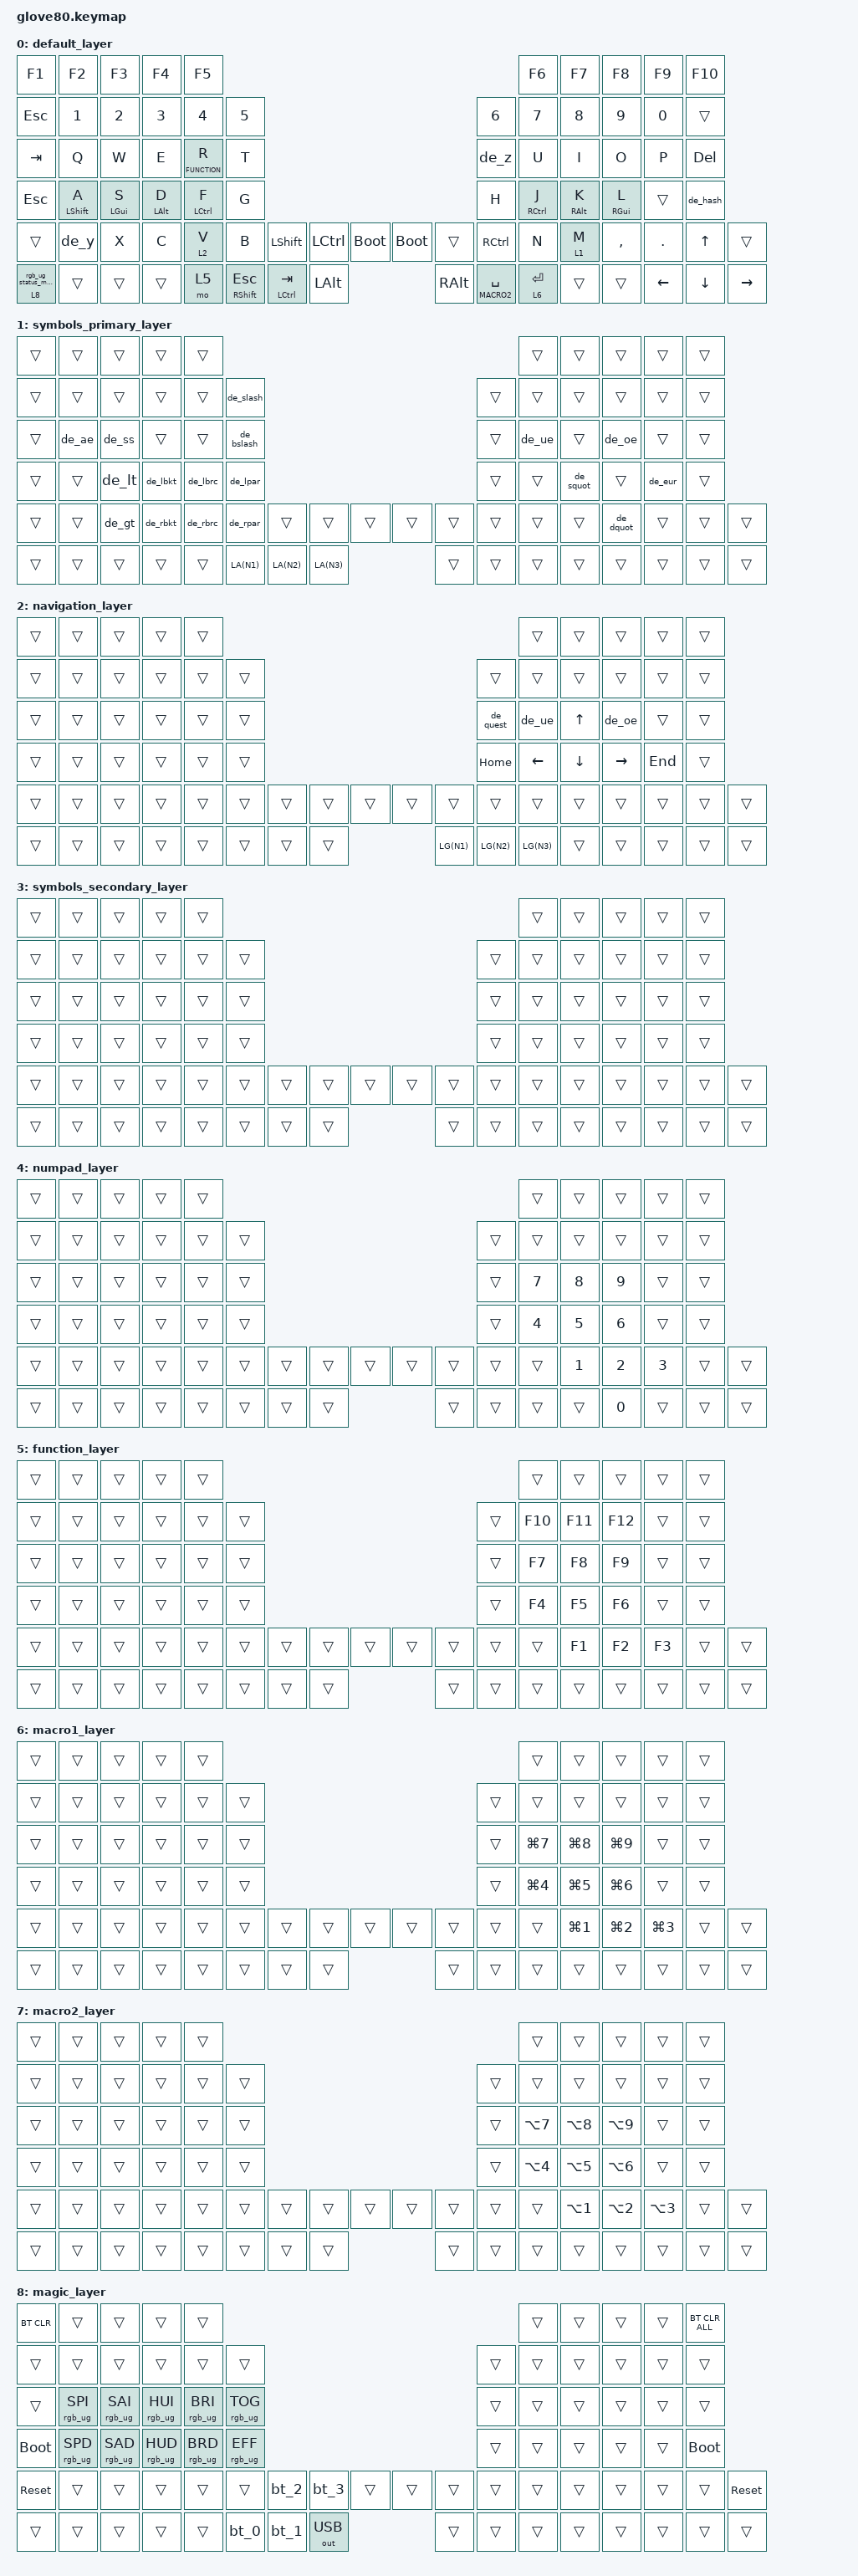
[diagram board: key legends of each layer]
#include <behaviors.dtsi>
#include <dt-bindings/zmk/bt.h>
#include <dt-bindings/zmk/keys.h>
#include <dt-bindings/zmk/outputs.h>
#include <dt-bindings/zmk/rgb.h>

// German umlauts and special characters >
#define DE_ESCAPE_CHARACTER (LC(ZMK_HID_USAGE(HID_USAGE_KEY, HID_USAGE_KEY_KEYBOARD_LEFT_BRACKET_AND_LEFT_BRACE)))
#define DE_FILE_SEPARATOR (LC(ZMK_HID_USAGE(HID_USAGE_KEY, HID_USAGE_KEY_KEYBOARD_BACKSLASH_AND_PIPE)))
#define DE_GROUP_SEPARATOR (LC(ZMK_HID_USAGE(HID_USAGE_KEY, HID_USAGE_KEY_KEYBOARD_RIGHT_BRACKET_AND_RIGHT_BRACE)))
#define DE_SPACE (ZMK_HID_USAGE(HID_USAGE_KEY, HID_USAGE_KEY_KEYBOARD_SPACEBAR))
#define DE_EXCLAMATION (LS(ZMK_HID_USAGE(HID_USAGE_KEY, HID_USAGE_KEY_KEYBOARD_1_AND_EXCLAMATION)))
#define DE_DOUBLE_QUOTES (LS(ZMK_HID_USAGE(HID_USAGE_KEY, HID_USAGE_KEY_KEYBOARD_2_AND_AT)))
#define DE_HASH (ZMK_HID_USAGE(HID_USAGE_KEY, HID_USAGE_KEY_KEYBOARD_BACKSLASH_AND_PIPE))
#define DE_DOLLAR (LS(ZMK_HID_USAGE(HID_USAGE_KEY, HID_USAGE_KEY_KEYBOARD_4_AND_DOLLAR)))
#define DE_PERCENT (LS(ZMK_HID_USAGE(HID_USAGE_KEY, HID_USAGE_KEY_KEYBOARD_5_AND_PERCENT)))
#define DE_AMPERSAND (LS(ZMK_HID_USAGE(HID_USAGE_KEY, HID_USAGE_KEY_KEYBOARD_6_AND_CARET)))
#define DE_SINGLE_QUOTE (LS(ZMK_HID_USAGE(HID_USAGE_KEY, HID_USAGE_KEY_KEYBOARD_BACKSLASH_AND_PIPE)))
#define DE_LEFT_PARENTHESIS (LS(ZMK_HID_USAGE(HID_USAGE_KEY, HID_USAGE_KEY_KEYBOARD_8_AND_ASTERISK)))
#define DE_RIGHT_PARENTHESIS (LS(ZMK_HID_USAGE(HID_USAGE_KEY, HID_USAGE_KEY_KEYBOARD_9_AND_LEFT_PARENTHESIS)))
#define DE_ASTERISK (LS(ZMK_HID_USAGE(HID_USAGE_KEY, HID_USAGE_KEY_KEYBOARD_RIGHT_BRACKET_AND_RIGHT_BRACE)))
#define DE_PLUS (ZMK_HID_USAGE(HID_USAGE_KEY, HID_USAGE_KEY_KEYBOARD_RIGHT_BRACKET_AND_RIGHT_BRACE))
#define DE_COMMA (ZMK_HID_USAGE(HID_USAGE_KEY, HID_USAGE_KEY_KEYBOARD_COMMA_AND_LESS_THAN))
#define DE_MINUS (ZMK_HID_USAGE(HID_USAGE_KEY, HID_USAGE_KEY_KEYBOARD_SLASH_AND_QUESTION_MARK))
#define DE_PERIOD (ZMK_HID_USAGE(HID_USAGE_KEY, HID_USAGE_KEY_KEYBOARD_PERIOD_AND_GREATER_THAN))
#define DE_SLASH (LS(ZMK_HID_USAGE(HID_USAGE_KEY, HID_USAGE_KEY_KEYBOARD_7_AND_AMPERSAND)))
#define DE_N0 (ZMK_HID_USAGE(HID_USAGE_KEY, HID_USAGE_KEY_KEYBOARD_0_AND_RIGHT_PARENTHESIS))
#define DE_N1 (ZMK_HID_USAGE(HID_USAGE_KEY, HID_USAGE_KEY_KEYBOARD_1_AND_EXCLAMATION))
#define DE_N2 (ZMK_HID_USAGE(HID_USAGE_KEY, HID_USAGE_KEY_KEYBOARD_2_AND_AT))
#define DE_N3 (ZMK_HID_USAGE(HID_USAGE_KEY, HID_USAGE_KEY_KEYBOARD_3_AND_HASH))
#define DE_N4 (ZMK_HID_USAGE(HID_USAGE_KEY, HID_USAGE_KEY_KEYBOARD_4_AND_DOLLAR))
#define DE_N5 (ZMK_HID_USAGE(HID_USAGE_KEY, HID_USAGE_KEY_KEYBOARD_5_AND_PERCENT))
#define DE_N6 (ZMK_HID_USAGE(HID_USAGE_KEY, HID_USAGE_KEY_KEYBOARD_6_AND_CARET))
#define DE_N7 (ZMK_HID_USAGE(HID_USAGE_KEY, HID_USAGE_KEY_KEYBOARD_7_AND_AMPERSAND))
#define DE_N8 (ZMK_HID_USAGE(HID_USAGE_KEY, HID_USAGE_KEY_KEYBOARD_8_AND_ASTERISK))
#define DE_N9 (ZMK_HID_USAGE(HID_USAGE_KEY, HID_USAGE_KEY_KEYBOARD_9_AND_LEFT_PARENTHESIS))
#define DE_COLON (LS(ZMK_HID_USAGE(HID_USAGE_KEY, HID_USAGE_KEY_KEYBOARD_PERIOD_AND_GREATER_THAN)))
#define DE_SEMICOLON (LS(ZMK_HID_USAGE(HID_USAGE_KEY, HID_USAGE_KEY_KEYBOARD_COMMA_AND_LESS_THAN)))
#define DE_LESS_THAN (ZMK_HID_USAGE(HID_USAGE_KEY, HID_USAGE_KEY_KEYBOARD_NON_US_BACKSLASH_AND_PIPE))
#define DE_EQUAL (LS(ZMK_HID_USAGE(HID_USAGE_KEY, HID_USAGE_KEY_KEYBOARD_0_AND_RIGHT_PARENTHESIS)))
#define DE_GREATER_THAN (LS(ZMK_HID_USAGE(HID_USAGE_KEY, HID_USAGE_KEY_KEYBOARD_NON_US_BACKSLASH_AND_PIPE)))
#define DE_QUESTION (LS(ZMK_HID_USAGE(HID_USAGE_KEY, HID_USAGE_KEY_KEYBOARD_MINUS_AND_UNDERSCORE)))
#define DE_AT_SIGN (RA(ZMK_HID_USAGE(HID_USAGE_KEY, HID_USAGE_KEY_KEYBOARD_Q)))
#define DE_LEFT_BRACKET (RA(ZMK_HID_USAGE(HID_USAGE_KEY, HID_USAGE_KEY_KEYBOARD_8_AND_ASTERISK)))
#define DE_BACKSLASH (RA(ZMK_HID_USAGE(HID_USAGE_KEY, HID_USAGE_KEY_KEYBOARD_MINUS_AND_UNDERSCORE)))
#define DE_RIGHT_BRACKET (RA(ZMK_HID_USAGE(HID_USAGE_KEY, HID_USAGE_KEY_KEYBOARD_9_AND_LEFT_PARENTHESIS)))
#define DE_CARET (ZMK_HID_USAGE(HID_USAGE_KEY, HID_USAGE_KEY_KEYBOARD_GRAVE_ACCENT_AND_TILDE))
#define DE_UNDERSCORE (LS(ZMK_HID_USAGE(HID_USAGE_KEY, HID_USAGE_KEY_KEYBOARD_SLASH_AND_QUESTION_MARK)))
#define DE_GRAVE (LS(ZMK_HID_USAGE(HID_USAGE_KEY, HID_USAGE_KEY_KEYBOARD_EQUAL_AND_PLUS)))
#define DE_Y (ZMK_HID_USAGE(HID_USAGE_KEY, HID_USAGE_KEY_KEYBOARD_Z))
#define DE_Z (ZMK_HID_USAGE(HID_USAGE_KEY, HID_USAGE_KEY_KEYBOARD_Y))
#define DE_LEFT_BRACE (RA(ZMK_HID_USAGE(HID_USAGE_KEY, HID_USAGE_KEY_KEYBOARD_7_AND_AMPERSAND)))
#define DE_PIPE (RA(ZMK_HID_USAGE(HID_USAGE_KEY, HID_USAGE_KEY_KEYBOARD_NON_US_BACKSLASH_AND_PIPE)))
#define DE_RIGHT_BRACE (RA(ZMK_HID_USAGE(HID_USAGE_KEY, HID_USAGE_KEY_KEYBOARD_0_AND_RIGHT_PARENTHESIS)))
#define DE_TILDE (RA(ZMK_HID_USAGE(HID_USAGE_KEY, HID_USAGE_KEY_KEYBOARD_RIGHT_BRACKET_AND_RIGHT_BRACE)))
#define DE_SECTION (LS(ZMK_HID_USAGE(HID_USAGE_KEY, HID_USAGE_KEY_KEYBOARD_3_AND_HASH)))
#define DE_DEGREE (LS(ZMK_HID_USAGE(HID_USAGE_KEY, HID_USAGE_KEY_KEYBOARD_GRAVE_ACCENT_AND_TILDE)))
#define DE_SUPER2 (RA(ZMK_HID_USAGE(HID_USAGE_KEY, HID_USAGE_KEY_KEYBOARD_2_AND_AT)))
#define DE_SUPER3 (RA(ZMK_HID_USAGE(HID_USAGE_KEY, HID_USAGE_KEY_KEYBOARD_3_AND_HASH)))
#define DE_ACUTE (ZMK_HID_USAGE(HID_USAGE_KEY, HID_USAGE_KEY_KEYBOARD_EQUAL_AND_PLUS))
#define DE_SHARP_S (LS(RA(ZMK_HID_USAGE(HID_USAGE_KEY, HID_USAGE_KEY_KEYBOARD_MINUS_AND_UNDERSCORE))))
#define DE_A_UMLAUT (ZMK_HID_USAGE(HID_USAGE_KEY, HID_USAGE_KEY_KEYBOARD_APOSTROPHE_AND_QUOTE))
#define DE_O_UMLAUT (ZMK_HID_USAGE(HID_USAGE_KEY, HID_USAGE_KEY_KEYBOARD_SEMICOLON_AND_COLON))
#define DE_U_UMLAUT (ZMK_HID_USAGE(HID_USAGE_KEY, HID_USAGE_KEY_KEYBOARD_LEFT_BRACKET_AND_LEFT_BRACE))
#define DE_EURO (RA(ZMK_HID_USAGE(HID_USAGE_KEY, HID_USAGE_KEY_KEYBOARD_E)))
// < German umlauts and special characters

// layers
#define DEFAULT 0
#define SYMBOLS_PRIMARY 1
#define NAVIGATION 2
#define SYMBOLS_SECONDARY 3
#define NUMPAD 4
#define FUNCTION 5
#define MACRO1 6
#define MACRO2 7
#define MAGIC 8

/ {
    // Positionsnummern für alle Tasten (für Kombos und andere Referenzen)
    // |  0       |  1      |  2       |  3        |  4         |                                                                                  |  5     |  6       |  7        |   8       |  9   |
    // |  10      |  11     |  12      |  13       |  14        |  15   |                                                                  |  16   |   17   |   18     |  19       |   20      |   21 |
    // |  22      |  23     |  24      |  25       |  26        |  27   |                                                                  |  28   |   29   |   30 I   |  31       |   32      |   33 |
    // |  34      |  35     |  36      |  37       |  38        |  39   |                                                                  |  40   |   41 J |   42 K   |  43       |   44      |   45 |
    // |  46      |  47     |  48      |  49       |  50        |  51   |   52      |   53      |   54    |  |   55    |   56    |   57    |  58   |   59   |   60 ,   |  61       |   62      |   63 |
    // |  64      |  65     |  66      |  67       |  68        |       |   69      |   70      |   71    |  |   72    |   73    |   74    |       |   75   |   76     |  77       |   78      |   79 |

    combos {
        compatible = "zmk,combos";

        // backspace jk

        combo_bspc {
            timeout-ms = <50>;
            key-positions = <41 42>; // J and K keys
            bindings = <&kp BACKSPACE>;
            layers = <0>;
        };

        // arrow up - I and K keys

        combo_up {
            timeout-ms = <50>;
            key-positions = <30 42>; // I and K keys
            bindings = <&kp UP>;
            layers = <0>;
        };

        // arrow down - K and comma keys

        combo_down {
            timeout-ms = <50>;
            key-positions = <42 60>; // K and comma keys
            bindings = <&kp DOWN>;
            layers = <0>;
        };

        //
        // // left bracket - U and I keys
        // combo_lbrc {
        //     timeout-ms = <50>;
        //     key-positions = <29 30>; // U and I keys
        //     bindings = <&kp LBKT>;
        //     layers = <0>;
        // };
        //
        // // right bracket - I and O keys
        // combo_rbrc {
        //     timeout-ms = <50>;
        //     key-positions = <30 31>; // I and O keys
        //     bindings = <&kp RBKT>;
        //     layers = <0>;
        // };
        //
        // // right curly brace - comma and dot keys
        // combo_rcbr {
        //     timeout-ms = <50>;
        //     key-positions = <60 61>; // comma and dot keys
        //     bindings = <&kp RBRC>;
        //     layers = <0>;
        // };
        //
        // // left parenthesis - 7 and 8 keys
        // combo_lprn {
        //     timeout-ms = <50>;
        //     key-positions = <17 18>; // 7 and 8 keys
        //     bindings = <&kp LPAR>;
        //     layers = <0>;
        // };
        //
        // // right parenthesis - 8 and 9 keys
        // combo_rprn {
        //     timeout-ms = <50>;
        //     key-positions = <18 19>; // 8 and 9 keys
        //     bindings = <&kp RPAR>;
        //     layers = <0>;
        // };
        //
        // // left curly brace - M and comma keys
        // combo_lcbr {
        //     timeout-ms = <50>;
        //     key-positions = <59 60>; // M and comma keys
        //     bindings = <&kp LBRC>;
        //     layers = <0>;
        // };
        //
        // // enter - J and M keys
        // combo_enter {
        //     timeout-ms = <50>;
        //     key-positions = <41 59>; // J and M keys
        //     bindings = <&kp ENTER>;
        //     layers = <0>;
        // };
        //
        // // tab - P and minus keys
        // combo_tab {
        //     timeout-ms = <50>;
        //     key-positions = <32 62>; // P and minus keys
        //     bindings = <&kp TAB>;
        //     layers = <0>;
        // };
    };

    behaviors {
        // For the "layer" key, it'd nice to be able to use it as either a shift or a toggle.
        // Configure it as a tap dance, so the first tap (or hold) is a &mo and the second tap is a &to
        // layer_td: tap_dance_0 {
        //     compatible = "zmk,behavior-tap-dance";
        //     label = "LAYER_TAP_DANCE";
        //     #binding-cells = <0>;
        //     tapping-term-ms = <200>;
        //     bindings = <&mo LOWER>, <&to LOWER>;
        // };

        magic: magic_hold_tap {
            compatible = "zmk,behavior-hold-tap";
            #binding-cells = <2>;
            flavor = "tap-preferred";
            tapping-term-ms = <200>;
            bindings = <&mo>, <&rgb_ug_status_macro>;
        };

        hm: homerow_mods {
            compatible = "zmk,behavior-hold-tap";
            #binding-cells = <2>;
            tapping-term-ms = <250>;
            quick-tap-ms = <0>;
            flavor = "tap-preferred";
            bindings = <&kp>, <&kp>;
        };
        
        mx: mx {
            compatible = "zmk,behavior-hold-tap";
            #binding-cells = <2>;
            tapping-term-ms = <250>;
            flavor = "tap-preferred";
            bindings = <&mo>, <&kp>;
        };
    };

macros {
        rgb_ug_status_macro: rgb_ug_status_macro_0 {
            label = "RGB_UG_STATUS";
            compatible = "zmk,behavior-macro";
            #binding-cells = <0>;
            bindings = <&rgb_ug RGB_STATUS>;
        };
 
        // German umlauts and special characters

        de_ae: de_ae { compatible = "zmk,behavior-macro"; #binding-cells = <0>; bindings = <&kp DE_A_UMLAUT>; };  // ä
        de_ss: de_ss { compatible = "zmk,behavior-macro"; #binding-cells = <0>; bindings = <&kp DE_SHARP_S>; };  // ß
        de_oe: de_oe { compatible = "zmk,behavior-macro"; #binding-cells = <0>; bindings = <&kp DE_O_UMLAUT>; };  // ö
        de_ue: de_ue { compatible = "zmk,behavior-macro"; #binding-cells = <0>; bindings = <&kp DE_U_UMLAUT>; };  // ü
        de_eur: de_eur { compatible = "zmk,behavior-macro"; #binding-cells = <0>; bindings = <&kp DE_EURO>; };  // €
        de_sect: de_sect { compatible = "zmk,behavior-macro"; #binding-cells = <0>; bindings = <&kp DE_SECTION>; };  // §
        de_deg: de_deg { compatible = "zmk,behavior-macro"; #binding-cells = <0>; bindings = <&kp DE_DEGREE>; };  // °
        de_square: de_square { compatible = "zmk,behavior-macro"; #binding-cells = <0>; bindings = <&kp DE_SUPER2>; };  // ²
        de_cube: de_cube { compatible = "zmk,behavior-macro"; #binding-cells = <0>; bindings = <&kp DE_SUPER3>; };  // ³
        de_acute: de_acute { compatible = "zmk,behavior-macro"; #binding-cells = <0>; bindings = <&kp DE_ACUTE>; };  // ´
        de_y: de_y { compatible = "zmk,behavior-macro"; #binding-cells = <0>; bindings = <&kp DE_Y>; };  // y (on German layout)
        de_z: de_z { compatible = "zmk,behavior-macro"; #binding-cells = <0>; bindings = <&kp DE_Z>; };  // z (on German layout)
        de_excl: de_excl { compatible =   "zmk,behavior-macro"; #binding-cells = <0>; bindings = <&kp DE_EXCLAMATION>; };  // !
        de_dollar: de_dollar { compatible = "zmk,behavior-macro"; #binding-cells = <0>; bindings = <&kp DE_DOLLAR>; };  // $
        de_percent: de_percent { compatible = "zmk,behavior-macro"; #binding-cells = <0>; bindings = <&kp DE_PERCENT>; };  // %
        de_plus: de_plus { compatible = "zmk,behavior-macro"; #binding-cells = <0>; bindings = <&kp DE_PLUS>; };  // +
        de_comma: de_comma { compatible = "zmk,behavior-macro"; #binding-cells = <0>; bindings = <&kp DE_COMMA>; };  // ,
        de_minus: de_minus { compatible = "zmk,behavior-macro"; #binding-cells = <0>; bindings = <&kp DE_MINUS>; };  // -
        de_period: de_period { compatible = "zmk,behavior-macro"; #binding-cells = <0>; bindings = <&kp DE_PERIOD>; };  // .
        de_colon: de_colon { compatible = "zmk,behavior-macro"; #binding-cells = <0>; bindings = <&kp DE_COLON>; };  // :
        de_semi: de_semi { compatible = "zmk,behavior-macro"; #binding-cells = <0>; bindings = <&kp DE_SEMICOLON>; };  // ;
        de_caret: de_caret { compatible = "zmk,behavior-macro"; #binding-cells = <0>; bindings = <&kp DE_CARET>; };  // ^
        de_under: de_under { compatible = "zmk,behavior-macro"; #binding-cells = <0>; bindings = <&kp DE_UNDERSCORE>; };  // _
        de_grave: de_grave { compatible = "zmk,behavior-macro"; #binding-cells = <0>; bindings = <&kp DE_GRAVE>; };  // `

        de_lt: de_lt { compatible = "zmk,behavior-macro"; #binding-cells = <0>; bindings = <&kp DE_LESS_THAN>; };  // <
        de_gt: de_gt { compatible = "zmk,behavior-macro"; #binding-cells = <0>; bindings = <&kp DE_GREATER_THAN>; };  // >
        de_lbkt: de_lbkt { compatible = "zmk,behavior-macro"; #binding-cells = <0>; bindings = <&kp DE_LEFT_BRACKET>; };  // [
        de_rbkt: de_rbkt { compatible = "zmk,behavior-macro"; #binding-cells = <0>; bindings = <&kp DE_RIGHT_BRACKET>; };  // ]
        de_lbrc: de_lbrc { compatible = "zmk,behavior-macro"; #binding-cells = <0>; bindings = <&kp DE_LEFT_BRACE>; };  // {
        de_rbrc: de_rbrc { compatible = "zmk,behavior-macro"; #binding-cells = <0>; bindings = <&kp DE_RIGHT_BRACE>; };  // }
        de_lpar: de_lpar { compatible = "zmk,behavior-macro"; #binding-cells = <0>; bindings = <&kp DE_LEFT_PARENTHESIS>; };  // (
        de_rpar: de_rpar { compatible = "zmk,behavior-macro"; #binding-cells = <0>; bindings = <&kp DE_RIGHT_PARENTHESIS>; };  // )

        de_squot: de_squot { compatible = "zmk,behavior-macro"; #binding-cells = <0>; bindings = <&kp DE_SINGLE_QUOTE>; };  // '
        de_dquot: de_dquot { compatible = "zmk,behavior-macro"; #binding-cells = <0>; bindings = <&kp DE_DOUBLE_QUOTES>; }; // 

        de_slash: de_slash { compatible = "zmk,behavior-macro"; #binding-cells = <0>; bindings = <&kp DE_SLASH>; };  // /
        de_bslash: de_bslash { compatible = "zmk,behavior-macro"; #binding-cells = <0>; bindings = <&kp DE_BACKSLASH>; };  // \

        de_quest: de_quest { compatible = "zmk,behavior-macro"; #binding-cells = <0>; bindings = <&kp DE_QUESTION>; };  // ?
        de_amp: de_amp { compatible = "zmk,behavior-macro"; #binding-cells = <0>; bindings = <&kp DE_AMPERSAND>; };  // &
        de_eq: de_eq { compatible = "zmk,behavior-macro"; #binding-cells = <0>; bindings = <&kp DE_EQUAL>; };  // =
        de_at: de_at { compatible = "zmk,behavior-macro"; #binding-cells = <0>; bindings = <&kp DE_AT_SIGN>; };  // @
        de_ast: de_ast { compatible = "zmk,behavior-macro"; #binding-cells = <0>; bindings = <&kp DE_ASTERISK>; };  // *
        de_hash: de_hash { compatible = "zmk,behavior-macro"; #binding-cells = <0>; bindings = <&kp DE_HASH>; };  // #
        de_pipe: de_pipe { compatible = "zmk,behavior-macro"; #binding-cells = <0>; bindings = <&kp DE_PIPE>; };  // |
        de_tilde: de_tilde { compatible = "zmk,behavior-macro"; #binding-cells = <0>; bindings = <&kp DE_TILDE>; };  // ~

        // hm_de_under: hm_de_under { compatible = "zmk,behavior-macro"; #binding-cells = <0>; bindings = <&hm RSHFT DE_MINUS>; };  // _
        
        // Number keys
        // de_n0: de_n0 { compatible = "zmk,behavior-macro"; #binding-cells = <0>; bindings = <&macro_press &kp DE_N0>; };  // 0
        // de_n1: de_n1 { compatible = "zmk,behavior-macro"; #binding-cells = <0>; bindings = <&macro_press &kp DE_N1>; };  // 1
        // de_n2: de_n2 { compatible = "zmk,behavior-macro"; #binding-cells = <0>; bindings = <&macro_press &kp DE_N2>; };  // 2
        // de_n3: de_n3 { compatible = "zmk,behavior-macro"; #binding-cells = <0>; bindings = <&macro_press &kp DE_N3>; };  // 3
        // de_n4: de_n4 { compatible = "zmk,behavior-macro"; #binding-cells = <0>; bindings = <&macro_press &kp DE_N4>; };  // 4
        // de_n5: de_n5 { compatible = "zmk,behavior-macro"; #binding-cells = <0>; bindings = <&macro_press &kp DE_N5>; };  // 5
        // de_n6: de_n6 { compatible = "zmk,behavior-macro"; #binding-cells = <0>; bindings = <&macro_press &kp DE_N6>; };  // 6
        // de_n7: de_n7 { compatible = "zmk,behavior-macro"; #binding-cells = <0>; bindings = <&macro_press &kp DE_N7>; };  // 7
        // de_n8: de_n8 { compatible = "zmk,behavior-macro"; #binding-cells = <0>; bindings = <&macro_press &kp DE_N8>; };  // 8
        // de_n9: de_n9 { compatible = "zmk,behavior-macro"; #binding-cells = <0>; bindings = <&macro_press &kp DE_N9>; };  // 9

        // Special control characters
        // de_esc_char: de_esc_char { compatible = "zmk,behavior-macro"; #binding-cells = <0>; bindings = <&macro_press &kp DE_ESCAPE_CHARACTER>; };  // Escape character
        // de_file_sep: de_file_sep { compatible = "zmk,behavior-macro"; #binding-cells = <0>; bindings = <&macro_press &kp DE_FILE_SEPARATOR>; };  // File separator
        // de_group_sep: de_group_sep { compatible = "zmk,behavior-macro"; #binding-cells = <0>; bindings = <&macro_press &kp DE_GROUP_SEPARATOR>; };  // Group separator
        // de_space: de_space { compatible = "zmk,behavior-macro"; #binding-cells = <0>; bindings = <&macro_press &kp DE_SPACE>; };  // Space

        // alt_x: alt_x {
        //     label = "ALT_X";
        //     compatible = "zmk,behavior-macro";
        //     #binding-cells = <0>;
        //     bindings
        //         = <&macro_press &kp LALT>,
        //           <&macro_tap &kp X>,
        //           <&macro_release &kp LALT>;
        // };
        // alt_left: alt_left {
        //     label = "ALT_LEFT";
        //     compatible = "zmk,behavior-macro";
        //     #binding-cells = <0>;
        //     bindings
        //         = <&macro_press &kp RALT>,
        //           <&macro_tap &kp LEFT>,
        //           <&macro_release &kp RALT>;
        // };
        // alt_dot: alt_dot {
        //     label = "ALT_DOT";
        //     compatible = "zmk,behavior-macro";
        //     #binding-cells = <0>;
        //     bindings
        //         = <&macro_press &kp RALT>,
        //           <&macro_tap &kp DOT>,
        //           <&macro_release &kp RALT>;
        // };
        // alt_right: alt_right {
        //     label = "ALT_RIGHT";
        //     compatible = "zmk,behavior-macro";
        //     #binding-cells = <0>;
        //     bindings
        //         = <&macro_press &kp RALT>,
        //           <&macro_tap &kp RIGHT>,
        //           <&macro_release &kp RALT>;
        // };
        // alt_up: alt_up {
        //     label = "ALT_UP";
        //     compatible = "zmk,behavior-macro";
        //     #binding-cells = <0>;
        //     bindings
        //         = <&macro_press &kp RALT>,
        //           <&macro_tap &kp UP>,
        //           <&macro_release &kp RALT>;
        // };
        // alt_down: alt_down {
        //     label = "ALT_DOWN";
        //     compatible = "zmk,behavior-macro";
        //     #binding-cells = <0>;
        //     bindings
        //         = <&macro_press &kp RALT>,
        //           <&macro_tap &kp DOWN>,
        //           <&macro_release &kp RALT>;
        // };


        bt_0: bt_profile_macro_0 {
            label = "BT_0";
            compatible = "zmk,behavior-macro";
            #binding-cells = <0>;
            bindings = <&out OUT_BLE &bt BT_SEL 0>;
        };

        bt_1: bt_profile_macro_1 {
            label = "BT_1";
            compatible = "zmk,behavior-macro";
            #binding-cells = <0>;
            bindings = <&out OUT_BLE &bt BT_SEL 1>;
        };

        bt_2: bt_profile_macro_2 {
            label = "BT_2";
            compatible = "zmk,behavior-macro";
            #binding-cells = <0>;
            bindings = <&out OUT_BLE &bt BT_SEL 2>;
        };

        bt_3: bt_profile_macro_3 {
            label = "BT_3";
            compatible = "zmk,behavior-macro";
            #binding-cells = <0>;
            bindings = <&out OUT_BLE &bt BT_SEL 3>;
        };
    };

    // ORIGINAL LAYOUT --------------------------------------------------------------------------------------------------------------------------
    // |  #1   |  #2 |  #3 |  #4  |  #5  |  #6  |  #7   |  #8   |  #9     |  #10  |  #11  |  #12  |  #13 |  #14  |  #15  |  #16 |  #17  |  #18 |
    // |  F1   |  F2 |  F3 |  F4  |  F5  |                                                               |  F6   |  F7   |  F8  |   F9  |  F10 |
    // |  =    |  1  |  2  |  3   |  4   |  5   |                                                 |  6   |   7   |   8   |  9   |   0   |   -  |
    // |  TAB  |  Q  |  W  |  E   |  R   |  T   |                                                 |  Y   |   U   |   I   |  O   |   P   |   \  |
    // |  ESC  |  A  |  S  |  D   |  F   |  G   |                                                 |  H   |   J   |   K   |  L   |   ;   |   '  |
    // |   `   |  Z  |  X  |  C   |  V   |  B   | LSHFT | LCTRL | LOWER | | LGUI  | RCTRL | RSHFT |  N   |   M   |   ,   |  .   |   /   | PGUP |
    // | MAGIC | HOME| END | LEFT | RIGHT|      | BSPC  | DEL   | LALT  | | RALT  | RET   | SPACE |      |  UP   | DOWN  |  [   |   ]   | PGDN |

    keymap {
        compatible = "zmk,keymap";

        //   [0] = LAYOUT_voyager(
        //     KC_ESCAPE,      KC_1,           KC_2,           KC_3,           KC_4,           KC_5,                                           KC_6,           KC_7,           KC_8,           KC_9,           KC_0,           KC_DELETE,      
        //     KC_TAB,         KC_Q,           KC_W,           KC_E,           LT(5,KC_R),     KC_T,                                           DE_Z,           KC_U,           KC_I,           KC_O,           KC_TRANSPARENT, ST_MACRO_0,     
        //     KC_TRANSPARENT, MT(MOD_LSFT, KC_A),KC_S,           KC_D,           LT(2,KC_F),     KC_G,                                           KC_H,           LT(1,KC_J),     KC_K,           KC_L,           MT(MOD_RSFT, KC_P),KC_RIGHT_SHIFT, 
        //     DE_LESS,        MT(MOD_LCTL, DE_Y),MT(MOD_LGUI, KC_X),MT(MOD_LALT, KC_C),LT(4,KC_V),     KC_B,                                           KC_N,           LT(3,KC_M),     MT(MOD_RALT, KC_COMMA),MT(MOD_RGUI, KC_DOT),MT(MOD_RCTL, DE_MINS),DE_MORE,        
        //                                                     MT(MOD_RSFT, KC_TAB),MT(MOD_LCTL, KC_ESCAPE),                                LT(6,KC_SPACE), LT(7,KC_ENTER)
        //   ),

        default_layer {
            // |  #1        |  #2            |  #3        |  #4           |  #5          |  #6   |  #7          |  #8          |  #9           |  #10      |  #11          |  #12         |  #13       |  #14         |  #15          |  #16          |  #17                    |  #18    |
            // |  ESC       |  1             |  2         |  3            |  4           |                                                                                                |  6         |  7           |  8            |  9            |  0                      | - none
            // |  TAB       |  Q             |  W         |  E            |  R           |  T    |                                                                         |  Z           |  U         |   I          |  O            |   P           | DELETE                  | \ DEL
            // |  ESC       |  A             |  S         |  D            |  F           |  G    |                                                                         |  H           |  J         |   K          |  L            |   P           | RSHIFT                  | 
            // |  `         |  Y             |  X         |  C            |  V           |  B    | LSHFT        | LCTRL        | LOWER   |     | LGUI      | RCTRL         | RSHFT        |  N         |   M          |   ,           |  .            |   -                     |  >     |
            // | MAGIC      | HOME           | END        | LEFT          | RIGHT        |       | TAB          | ESC          | LALT    |     | RALT      | SPACE         | ENTER        |            |  UP          | DOWN          |  [            |   ]                     | PGDN   |

            bindings = <
                &kp F1      &kp F2         &kp F3       &kp F4       &kp F5                                                                                                                 &kp F6        &kp F7       &kp F8          &kp F9                 &kp F10
                &kp ESC     &kp N1         &kp N2       &kp N3       &kp N4          &kp N5                                                                                         &kp N6  &kp N7        &kp N8       &kp N9          &kp N0                 &trans
                &kp TAB     &kp Q          &kp W        &kp E        &lt FUNCTION R  &kp T                                                                                          &de_z   &kp U         &kp I        &kp O           &kp P                  &kp DEL
                &kp ESC     &hm LSHFT A    &hm LGUI S   &hm LALT D  &hm LCTRL F      &kp G                                                                                          &kp H   &hm RCTRL J   &hm RALT K   &hm RGUI L      &trans                  &de_hash
                &trans       &de_y          &kp X        &kp C        &lt 2 V         &kp B   &kp LSHFT      &kp LCTRL      &bootloader    &bootloader  &trans            &kp RCTRL  &kp N   &lt 1 M       &kp COMMA    &kp DOT         &kp UP                 &trans
                &magic 8 0  &trans          &trans        &trans        &mo 5                   &mt RSHFT ESC  &mt LCTRL TAB  &kp LALT       &kp RALT     &lt MACRO2 SPACE  &lt 6 RET          &trans        &trans        &kp LEFT        &kp DOWN               &kp RIGHT
            >;
        };

// 1
symbols_primary_layer {
            // |  #1      |  #2         |  #3          |  #4       |  #5            |  #6          |  #7       |  #8       |  #9       |  #10      |  #11    |  #12        |  #13          |  #14          |  #15           |  #16          |  #17          |  #18    |

            bindings = <
              &trans  &trans    &trans    &trans       &trans                                                                         &trans   &trans      &trans  &trans   &trans
              &trans  &trans    &trans    &trans       &trans         &de_slash                                                &trans  &trans   &trans      &trans  &trans   &trans
              &trans  &de_ae   &de_ss   &trans       &trans         &de_bslash                                               &trans  &de_ue  &trans      &de_oe &trans   &trans
              &trans  &trans    &de_lt   &de_lbkt    &de_lbrc      &de_lpar                                                 &trans  &trans   &de_squot  &trans  &de_eur &trans
              &trans  &trans    &de_gt   &de_rbkt    &de_rbrc      &de_rpar   &trans  &trans  &trans      &trans  &trans  &trans  &trans  &trans  &de_dquot  &trans  &trans   &trans
              &trans  &trans    &trans    &trans       &trans                   LA(N1)  LA(N2)  LA(N3)    &trans  &trans  &trans         &trans   &trans      &trans  &trans   &trans
            >;
        };

// 2
navigation_layer {
            // |  #1        |  #2          |  #3            |  #4          |  #5            |  #6           |  #7       |  #8       |  #9       |  #10      |  #11     |  #12         |  #13          |  #14          |  #15          |  #16         |  #17          |  #18    |

            bindings = <
                &trans   &trans  &trans  &trans  &trans                                                                     &trans    &trans    &trans     &trans    &trans
                &trans   &trans  &trans  &trans  &trans  &trans                                                 &trans        &trans    &trans    &trans     &trans    &trans
                &trans   &trans  &trans  &trans  &trans  &trans                                                 &de_quest    &de_ue   &kp UP   &de_oe    &trans    &trans
                &trans   &trans  &trans  &trans  &trans  &trans                                                 &kp HOME     &kp LEFT &kp DOWN &kp RIGHT &kp END  &trans
                &trans   &trans  &trans  &trans  &trans  &trans   &trans  &trans  &trans    &trans   &trans   &trans  &trans        &trans    &trans    &trans     &trans    &trans
                &trans   &trans  &trans  &trans  &trans          &trans  &trans  &trans    LG(N1)  LG(N2)  LG(N3)              &trans    &trans    &trans     &trans    &trans
            >;
        };

// 3
symbols_secondary_layer {
            // |  #1        |  #2          |  #3            |  #4           |  #5           |  #6            |  #7       |  #8       |  #9       |  #10     |  #11     |  #12         |  #13          |  #14          |  #15          |  #16         |  #17          |  #18    |

            bindings = <
&trans  &trans  &trans  &trans  &trans                                                            &trans  &trans  &trans  &trans  &trans
&trans  &trans  &trans  &trans  &trans  &trans                                              &trans  &trans  &trans  &trans  &trans  &trans
&trans  &trans  &trans  &trans  &trans  &trans                                              &trans  &trans  &trans  &trans  &trans  &trans
&trans  &trans  &trans  &trans  &trans  &trans                                              &trans  &trans  &trans  &trans  &trans  &trans
&trans  &trans  &trans  &trans  &trans  &trans  &trans  &trans  &trans    &trans  &trans  &trans  &trans  &trans  &trans  &trans  &trans  &trans
&trans  &trans  &trans  &trans  &trans         &trans  &trans  &trans    &trans  &trans  &trans         &trans  &trans  &trans  &trans  &trans
            >;
        };

        // 4
        numpad_layer {
            // |  #1        |  #2          |  #3            |  #4           |  #5            |  #6          |  #7       |  #8      |  #9       |  #10     |  #11     |  #12         |  #13          |  #14          |  #15          |  #16          |  #17          |  #18    |

            bindings = <
&trans     &trans   &trans   &trans   &trans                                                            &trans         &trans         &trans         &trans  &trans
&trans    &trans   &trans   &trans   &trans  &trans                                              &trans  &trans         &trans         &trans         &trans  &trans
&trans     &trans  &trans   &trans   &trans  &trans                                              &trans  &kp NUMBER_7  &kp NUMBER_8  &kp NUMBER_9  &trans  &trans
&trans     &trans   &trans  &trans   &trans  &trans                                              &trans  &kp NUMBER_4  &kp NUMBER_5  &kp NUMBER_6  &trans  &trans
&trans     &trans   &trans   &trans  &trans  &trans  &trans  &trans  &trans    &trans  &trans  &trans  &trans  &kp NUMBER_1  &kp NUMBER_2  &kp NUMBER_3  &trans  &trans
&trans     &trans   &trans   &trans  &trans         &trans  &trans  &trans    &trans  &trans  &trans         &trans         &kp NUMBER_0  &trans         &trans  &trans
            >;
        };



        // 5
        function_layer {
            // |  #1        |  #2          |  #3            |  #4           |  #5            |  #6          |  #7       |  #8      |  #9       |  #10     |  #11     |  #12         |  #13          |  #14          |  #15          |  #16          |  #17          |  #18    |

            bindings = <
&trans   &trans  &trans  &trans  &trans                                                            &trans         &trans         &trans         &trans   &trans
&trans   &trans  &trans  &trans  &trans  &trans                                              &trans  &kp F10       &kp F11       &kp F12       &trans   &trans
&trans   &trans  &trans  &trans  &trans  &trans                                              &trans  &kp F7        &kp F8        &kp F9        &trans   &trans 
&trans   &trans  &trans  &trans  &trans  &trans                                              &trans  &kp F4        &kp F5        &kp F6        &trans   &trans
&trans   &trans  &trans  &trans  &trans  &trans  &trans  &trans  &trans    &trans  &trans  &trans  &trans  &kp F1        &kp F2        &kp F3        &trans   &trans
&trans   &trans  &trans  &trans  &trans         &trans  &trans  &trans    &trans  &trans  &trans         &trans         &trans         &trans         &trans   &trans
            >;
        };

        // 6
        macro1_layer {
            // |  #1        |  #2          |  #3            |  #4           |  #5            |  #6          |  #7       |  #8      |  #9       |  #10     |  #11     |  #12         |  #13          |  #14          |  #15          |  #16          |  #17          |  #18    |

            bindings = <
&trans       &trans  &trans  &trans  &trans                                                            &trans  &trans       &trans       &trans       &trans
&trans       &trans  &trans  &trans  &trans  &trans                                              &trans  &trans  &trans       &trans       &trans       &trans
&trans       &trans  &trans  &trans  &trans  &trans                                              &trans  &kp LG(N7)  &kp LG(N8)  &kp LG(N9)  &trans  &trans
&trans       &trans  &trans  &trans  &trans  &trans                                              &trans  &kp LG(N4)  &kp LG(N5)  &kp LG(N6)  &trans  &trans
&trans       &trans  &trans  &trans  &trans  &trans  &trans  &trans  &trans    &trans  &trans  &trans  &trans  &kp LG(N1)  &kp LG(N2)  &kp LG(N3)  &trans  &trans
&trans       &trans  &trans  &trans  &trans         &trans  &trans  &trans    &trans  &trans  &trans         &trans       &trans       &trans       &trans  &trans
            >;
        };

        // 7
        macro2_layer {
            // |  #1        |  #2          |  #3            |  #4           |  #5            |  #6          |  #7       |  #8      |  #9       |  #10     |  #11     |  #12         |  #13          |  #14          |  #15          |  #16          |  #17          |  #18    |

            bindings = <
&trans       &trans  &trans  &trans  &trans                                                            &trans  &trans       &trans       &trans       &trans
&trans       &trans  &trans  &trans  &trans  &trans                                              &trans  &trans  &trans       &trans       &trans       &trans
&trans       &trans  &trans  &trans  &trans  &trans                                              &trans  &kp LA(N7)  &kp LA(N8)  &kp LA(N9)  &trans  &trans
&trans       &trans  &trans  &trans  &trans  &trans                                              &trans  &kp LA(N4)  &kp LA(N5)  &kp LA(N6)  &trans  &trans
&trans       &trans  &trans  &trans  &trans  &trans  &trans  &trans  &trans    &trans  &trans  &trans  &trans  &kp LA(N1)  &kp LA(N2)  &kp LA(N3)  &trans  &trans
&trans       &trans  &trans  &trans  &trans         &trans  &trans  &trans    &trans  &trans  &trans         &trans       &trans       &trans       &trans  &trans
            >;
        };

        // 8
        magic_layer {
            // |  #1        |  #2                |  #3            |  #4           |  #5            |  #6           |  #7       |  #8      |  #9           |  #10     |  #11     |  #12     |  #13     |  #14     |  #15     |  #16     |  #17     |  #18    |

            bindings = <
&bt BT_CLR   &trans            &trans            &trans            &trans                                                                                       &trans  &trans  &trans  &trans  &bt BT_CLR_ALL
&trans        &trans            &trans            &trans            &trans            &trans                                                               &trans  &trans  &trans  &trans  &trans  &trans
&trans        &rgb_ug RGB_SPI  &rgb_ug RGB_SAI  &rgb_ug RGB_HUI  &rgb_ug RGB_BRI  &rgb_ug RGB_TOG                                                     &trans  &trans  &trans  &trans  &trans  &trans
&bootloader  &rgb_ug RGB_SPD  &rgb_ug RGB_SAD  &rgb_ug RGB_HUD  &rgb_ug RGB_BRD  &rgb_ug RGB_EFF                                                     &trans  &trans  &trans  &trans  &trans  &bootloader
&sys_reset   &trans            &trans            &trans            &trans            &trans            &bt_2  &bt_3  &trans           &trans  &trans  &trans  &trans  &trans  &trans  &trans  &trans  &sys_reset
&trans        &trans            &trans            &trans            &trans                             &bt_0  &bt_1  &out OUT_USB    &trans  &trans  &trans         &trans  &trans  &trans  &trans  &trans
            >;
        };
    };
};


